# cyw20829 register map
Vendor: Cypress Semiconductor; Series: CYW20829; File version: 1.0
CPU: CM33 r0p1, little endian, MPU, FPU, VTOR, 3 interrupt priority bits
Registers are 32-bit, read-write, reset 0x0 unless marked. A register's access mark holds for its fields unless they carry their own. Offsets are from the block's base; [hi:lo] are bit positions; lines under a group give offsets from that group; {n}, {i} and the like mark numbered series; 'fields as' and 'values as' point back to an identical list; <NAME> marks a mode.

## SRSS (part 3 of 3) — SRSS Core Registers
Base 0x40200000
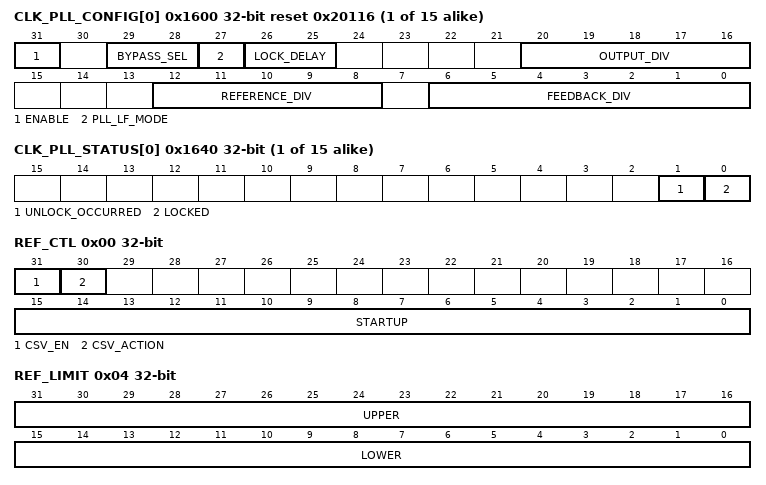
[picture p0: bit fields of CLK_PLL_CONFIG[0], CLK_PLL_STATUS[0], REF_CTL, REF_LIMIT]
{0x1600+4i} CLK_PLL_CONFIG[{i}] (i=0..14) reset 0x20116 — PLL Configuration Register
  [31] ENABLE — Master enable for PLL. Setup FEEDBACK_DIV, REFERENCE_DIV, and OUTPUT_DIV at least one cycle before setting ENABLE=1. Fpll = (FEEDBACK_DIV) * (Fref / REFERENCE_DIV) / (OUTPUT_DIV) 0: Block is disabled. When the PLL disables, hardware controls the bypass mux as described in BYPASS_SEL, before disabling the PLL circuit. 1: Block is enabled
  [29:28] BYPASS_SEL — Bypass mux located just after PLL output. This selection is glitch-free and can be changed while the PLL is running. When changing BYPASS_SEL, do not turn off the reference clock or PLL clock for five cycles (whichever is slower).
    0=AUTO (Automatic using lock indicator. When unlocked, automatically selects PLL reference input (bypass mode). When locked, automatically selects PLL output. If ENABLE=0, automatically selects PLL reference input.); 1=LOCKED_OR_NOTHING (Similar to AUTO, except the clock is gated off when unlocked. This is compatible with clock supervision, because the supervisors allow no clock during startup (until a timeout occurs), and the clock targets the proper frequency whenever it is running. If ENABLE=0, no clock is output.); 2=PLL_REF (Select PLL reference input (bypass mode). Ignores lock indicator); 3=PLL_OUT (Select PLL output. Ignores lock indicator. If ENABLE=0, no clock is output.)
  [27] PLL_LF_MODE — VCO frequency range selection. Configure this bit according to the targeted VCO frequency. Do not change this setting while the PLL is enabled. 0: VCO frequency is [200MHz, 400MHz] 1: VCO frequency is [170MHz, 200MHz)
  [26:25] LOCK_DELAY
  [20:16] OUTPUT_DIV — Control bits for Output divider. Set the divide value before enabling the PLL, and do not change it while PLL is enabled. 0: illegal (undefined behavior) 1: illegal (undefined behavior) 2: divide by 2. Suitable for direct usage as HFCLK source. ... 16: divide by 16. Suitable for direct usage as HFCLK source. >16: illegal (undefined behavior)
  [12:8] REFERENCE_DIV — Control bits for reference divider. Set the divide value before enabling the PLL, and do not change it while PLL is enabled. 0: illegal (undefined behavior) 1: divide by 1 ... 20: divide by 20 others: illegal (undefined behavior)
  [6:0] FEEDBACK_DIV — Control bits for feedback divider. Set the divide value before enabling the PLL, and do not change it while PLL is enabled. 0-21: illegal (undefined behavior) 22: divide by 22 ... 112: divide by 112 >112: illegal (undefined behavior)
{0x1640+4i} CLK_PLL_STATUS[{i}] (i=0..14) — PLL Status Register
  [1] UNLOCK_OCCURRED — This bit sets whenever the PLL Lock bit goes low, and stays set until cleared by firmware.
  [0] LOCKED ro — PLL Lock Indicator
0x1700 CSV_REF_SEL — Select CSV Reference clock for Active domain
  [2:0] REF_MUX — Selects a source for clock clk_ref_hf. Note that not all products support all clock sources. Selecting a clock source that is not supported will result in undefined behavior. It takes four cycles of the originally selected clock to switch away from it. Do not disable the original clock during this time.
    0=IMO (IMO - Internal R/C Oscillator); 1=EXTCLK (EXTCLK - External Clock Pin); 2=ECO (ECO - External-Crystal Oscillator); 3=ALTHF (ALTHF - Alternate High-Frequency clock input (product-specific clock)); 4=IHO (IHO - Internal High-speed Oscillator)
0x1710 CSV_REF group — CSV registers for the CSV Reference clock
  0x00 CSV group — Active domain Clock Supervisor (CSV) registers for CSV Reference clock
    0x00 REF_CTL — Clock Supervision Reference Control
      [31] CSV_EN — Enables clock supervision, both frequency and loss. CSV in Active domain: Clock supervision is reset during DeepSleep and Hibernate modes. When enabled it begins operating automatically after a DeepSleep wakeup, but it must be reconfigured after Hibernate wakeup. CSV in DeepSleep domain: Clock supervision is reset during Hibernate mode. It must be reconfigured after Hibernate wakeup. A CSV error detection is reported to the Fault structure, or instead it can generate a power reset.
      [30] CSV_ACTION — Specifies the action taken when an anomaly is detected on the monitored clock. CSV in DeepSleep domain always do a Fault report (which also wakes up the system).
        0=FAULT (Generate a fault); 1=RESET (Cause a power reset. This should only be used for clk_hf0.)
      [15:0] STARTUP — Startup delay time -1 (in reference clock cycles), after enable or DeepSleep wakeup, from reference clock start to monitored clock start. At a minimum (both clocks running): STARTUP >= (PERIOD +3) * FREQ_RATIO - UPPER, with FREQ_RATIO = (Reference frequency / Monitored frequency) On top of that the actual clock startup delay and the margin for accuracy of both clocks must be added.
    0x04 REF_LIMIT — Clock Supervision Reference Limits
      [31:16] UPPER — Cycle time upper limit. Set the upper limit -1, in reference clock cycles, before (or same time) the next monitored clock event must happen. If a monitored clock event does not happen before this limit is reached, or does not happen at all (clock loss), a CSV error is detected.
      [15:0] LOWER — Cycle time lower limit. Set the lower limit -1, in reference clock cycles, before the next monitored clock event is allowed to happen. If a monitored clock event happens before this limit is reached a CSV error is detected. LOWER must be at least 1 less than UPPER. In case the clocks are asynchronous LOWER must be at least 3 less than UPPER.
    0x08 MON_CTL — Clock Supervision Monitor Control
      [15:0] PERIOD — Period time. Set the Period -1, in monitored clock cycles, before the next monitored clock event happens. PERIOD <= (UPPER+1) / FREQ_RATIO -1, with FREQ_RATIO = (Reference frequency / Monitored frequency) In case the clocks are asynchronous: PERIOD <= UPPER / FREQ_RATIO -1 Additionally margin must be added for accuracy of both clocks.
0x1720 CSV_LF group — CSV registers for LF clock
  0x00 CSV group — LF clock Clock Supervisor registers
    0x00 REF_CTL — Clock Supervision Reference Control
      [31] CSV_EN — Enables clock supervision, both frequency and loss. CSV in Active domain: Clock supervision is reset during DeepSleep and Hibernate modes. When enabled it begins operating automatically after a DeepSleep wakeup, but it must be reconfigured after Hibernate wakeup. CSV in DeepSleep domain: Clock supervision is reset during Hibernate mode. It must be reconfigured after Hibernate wakeup. CSV in Backup domain: Clock supervision operates during Hibernate mode, can be configured to wake from Hibernate, and continues operating during reboot. A CSV error detection is reported to the Fault structure.
      [7:0] STARTUP — Startup delay time -1 (in reference clock cycles), after enable, from reference clock start to monitored clock start. At a minimum (both clocks running): STARTUP >= (PERIOD +3) * FREQ_RATIO - UPPER, with FREQ_RATIO = (Reference frequency / Monitored frequency) On top of that the actual clock startup delay and the margin for accuracy of both clocks must be added.
    0x04 REF_LIMIT — Clock Supervision Reference Limits
      [23:16] UPPER — Cycle time upper limit. Set the upper limit -1, in reference clock cycles, before (or same time) the next monitored clock event must happen. If a monitored clock event does not happen before this limit is reached, or does not happen at all (clock loss), a CSV error is detected.
      [7:0] LOWER — Cycle time lower limit. Set the lower limit -1, in reference clock cycles, before the next monitored clock event is allowed to happen. If a monitored clock event happens before this limit is reached a CSV error is detected. LOWER must be at least 1 less than UPPER. In case the clocks are asynchronous LOWER must be at least 3 less than UPPER.
    0x08 MON_CTL — Clock Supervision Monitor Control
      [7:0] PERIOD — Period time. Set the Period -1, in monitored clock cycles, before the next monitored clock event happens. PERIOD <= (UPPER+1) / FREQ_RATIO -1, with FREQ_RATIO = (Reference frequency / Monitored frequency) In case the clocks are asynchronous: PERIOD <= UPPER / FREQ_RATIO -1 Additionally margin must be added for accuracy of both clocks.
0x1730 CSV_ILO group — CSV registers for ILO clock
  0x00 CSV group — HVILO clock DeepSleep domain Clock Supervisor registers
    0x00 REF_CTL — Clock Supervision Reference Control
      fields as CSV_LF.CSV.REF_CTL
    0x04 REF_LIMIT — Clock Supervision Reference Limits
      fields as CSV_LF.CSV.REF_LIMIT
    0x08 MON_CTL — Clock Supervision Monitor Control
      fields as CSV_LF.CSV.MON_CTL
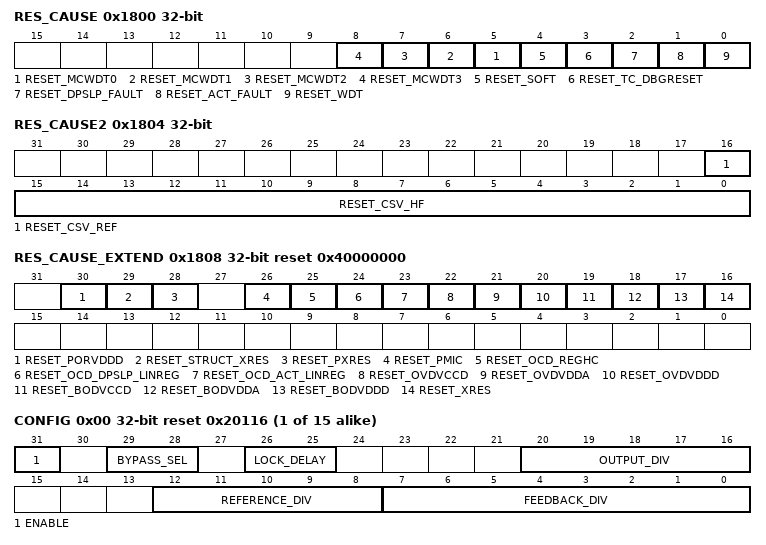
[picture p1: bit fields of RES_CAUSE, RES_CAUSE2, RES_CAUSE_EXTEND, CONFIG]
0x1800 RES_CAUSE — Reset Cause Observation Register
  [n+5] RESET_MCWDT{n} (n=0..3) — Multi-Counter Watchdog timer reset #{n}. This is a low-voltage cause bit that hardware clears when the low-voltage supply is initialized (see comments above).
  [4] RESET_SOFT — A CPU requested a system reset through it's SYSRESETREQ. This can be done via a debugger probe or in firmware. This is a low-voltage cause bit that hardware clears when the low-voltage supply is initialized (see comments above).
  [3] RESET_TC_DBGRESET — Test controller or debugger asserted reset. Only resets debug domain. This is a low-voltage cause bit that hardware clears when the low-voltage supply is initialized (see comments above).
  [2] RESET_DPSLP_FAULT
  [1] RESET_ACT_FAULT
  [0] RESET_WDT — A basic WatchDog Timer (WDT) reset has occurred since last power cycle. ULP products: This is a low-voltage cause bit that hardware clears when the low-voltage supply is initialized (see comments above). For products that support high-voltage cause detection, this bit blocks recording of other high-voltage cause bits, except RESET_PORVDDD. Hardware clears this bit during POR. This bit is not blocked by other HV cause bits.
0x1804 RES_CAUSE2 — Reset Cause Observation Register 2
  [16] RESET_CSV_REF — Clock supervision logic requested a reset due to loss or frequency violation of the reference clock source that is used to monitor the other HF clock sources.
  [15:0] RESET_CSV_HF — Clock supervision logic requested a reset due to loss or frequency violation of a high-frequency clock. Each bit index K corresponds to a HFCLK<K>. Unimplemented clock bits return zero.
0x1808 RES_CAUSE_EXTEND reset 0x40000000 — Extended Reset Cause Observation Register
  [30] RESET_PORVDDD — Indicator that a POR occurred. This is a high-voltage cause bit, and hardware clears the other bits when this one is set. It does not block further recording of other high-voltage causes.
  [29] RESET_STRUCT_XRES — Structural reset was asserted. This is a high-voltage cause bit that blocks recording of other high-voltage cause bits, except RESET_PORVDDD. Hardware clears this bit during POR. This bit is not blocked by other HV cause bits.
  [28] RESET_PXRES — PXRES triggered. This is a high-voltage cause bit that blocks recording of other high-voltage cause bits, except RESET_PORVDDD. Hardware clears this bit during POR. This bit is not blocked by other HV cause bits.
  [26] RESET_PMIC — PMIC status triggered a reset. If PMIC control is not present, hardware will never set this bit. This is a high-voltage cause bit that blocks recording of other high-voltage cause bits, except RESET_PORVDDD. Hardware clears this bit during POR.
  [25] RESET_OCD_REGHC — Overcurrent detection from REGHC (if present). If REGHC is not present, hardware will never set this bit. This is a high-voltage cause bit that blocks recording of other high-voltage cause bits, except RESET_PORVDDD. Hardware clears this bit during POR.
  [24] RESET_OCD_DPSLP_LINREG — Overcurrent detection on the internal VCCD supply when supplied by the DEEPSLEEP power mode linear regulator. This is a high-voltage cause bit that blocks recording of other high-voltage cause bits, except RESET_PORVDDD. Hardware clears this bit during POR.
  [23] RESET_OCD_ACT_LINREG — Overcurrent detection on the internal VCCD supply when supplied by the ACTIVE power mode linear regulator. This is a high-voltage cause bit that blocks recording of other high-voltage cause bits, except RESET_PORVDDD. Hardware clears this bit during POR.
  [22] RESET_OVDVCCD — Overvoltage detection on the internal core VCCD supply. This is a high-voltage cause bit that blocks recording of other high-voltage cause bits, except RESET_PORVDDD. Hardware clears this bit during POR.
  [21] RESET_OVDVDDA — Overvoltage detection on the external VDDA supply. This is a high-voltage cause bit that blocks recording of other high-voltage cause bits, except RESET_PORVDDD. Hardware clears this bit during POR.
  [20] RESET_OVDVDDD — Overvoltage detection on the external VDDD supply. This is a high-voltage cause bit that blocks recording of other high-voltage cause bits, except RESET_PORVDDD. Hardware clears this bit during POR.
  [19] RESET_BODVCCD — Internal VCCD core supply crossed the brown-out limit. Note that this detector will detect gross issues with the internal core supply, but may not catch all brown-out conditions. Functional and timing supervision (CSV, WDT) is provided to create fully failsafe internal crash detection. This is a high-voltage cause bit that blocks recording of other high-voltage cause bits, except RESET_PORVDDD. Hardware clears this bit during POR.
  [18] RESET_BODVDDA — External VDDA supply crossed the brown-out limit. This is a high-voltage cause bit that blocks recording of other high-voltage cause bits, except RESET_PORVDDD. Hardware clears this bit during POR.
  [17] RESET_BODVDDD — External VDDD supply crossed brown-out limit. Note that this cause will only be observable as long as the VDDD supply does not go below the POR (power on reset) detection limit. Below this limit it is not possible to reliably retain information in the device. This is a high-voltage cause bit that blocks recording of other high-voltage cause bits, except RESET_PORVDDD. Hardware clears this bit during POR.
  [16] RESET_XRES — External XRES pin was asserted. This is a high-voltage cause bit that blocks recording of other high-voltage cause bits, except RESET_PORVDDD. Hardware clears this bit during POR. This bit is not blocked by other HV cause bits.
0x1814 RES_PXRES_CTL wo — Programmable XRES Control Register
  [0] PXRES_TRIGGER — Triggers PXRES. This causes a full-scope reset and reboot.
{0x1900+0x10*i} CLK_PLL400M[{i}] (i=0..14) group — 400MHz PLL Configuration Register
  0x00 CONFIG reset 0x20116 — 400MHz PLL Configuration Register
    [31] ENABLE — Master enable for PLL. Setup FEEDBACK_DIV, REFERENCE_DIV, and OUTPUT_DIV at least one cycle before setting ENABLE=1. fOUT = (FEEDBACK_DIV + FRAC_EN*FRAC_DIV/2^24) * (fREF / REFERENCE_DIV) / (OUTPUT_DIV) 0: Block is disabled. When the PLL disables, hardware controls the bypass mux as described in BYPASS_SEL, before disabling the PLL circuit. 1: Block is enabled
    [29:28] BYPASS_SEL — Bypass mux located just after PLL output. This selection is glitch-free and can be changed while the PLL is running. When changing BYPASS_SEL, do not turn off the reference clock or PLL clock for five cycles (whichever is slower).
      0=AUTO (Automatic using lock indicator. When unlocked, automatically selects PLL reference input (bypass mode). When locked, automatically selects PLL output. If ENABLE=0, automatically selects PLL reference input.); 1=LOCKED_OR_NOTHING (Similar to AUTO, except the clock is gated off when unlocked. This is compatible with clock supervision, because the supervisors allow no clock during startup (until a timeout occurs), and the clock targets the proper frequency whenever it is running. If ENABLE=0, no clock is output.); 2=PLL_BYPASS (Select PLL reference input (bypass mode). Ignores lock indicator); 3=PLL_OUT (Select PLL output. Ignores lock indicator. If ENABLE=0, no clock is output.)
    [26:25] LOCK_DELAY
    [20:16] OUTPUT_DIV — Control bits for Output divider. Set the divide value before enabling the PLL, and do not change it while PLL is enabled. 0: illegal (undefined behavior) 1: illegal (undefined behavior) 2: divide by 2. Suitable for direct usage as HFCLK source. ... 16: divide by 16. Suitable for direct usage as HFCLK source. >16: illegal (undefined behavior)
    [12:8] REFERENCE_DIV — Control bits for reference divider. Set the divide value before enabling the PLL, and do not change it while PLL is enabled. 0: illegal (undefined behavior) 1: divide by 1 ... 16: divide by 16 others: illegal (undefined behavior) When using fractional mode, the jitter specs are met over the restricted range of 1 to 4, inclusive.
    [7:0] FEEDBACK_DIV — Control bits for feedback divider. Set the divide value before enabling the PLL, and do not change it while PLL is enabled. 0-15: illegal (undefined behavior) 16: divide by 16 ... 200: divide by 200 >200: illegal (undefined behavior) When using fractional mode, the jitter specs are met over the restricted range of 27 to 47, inclusive.
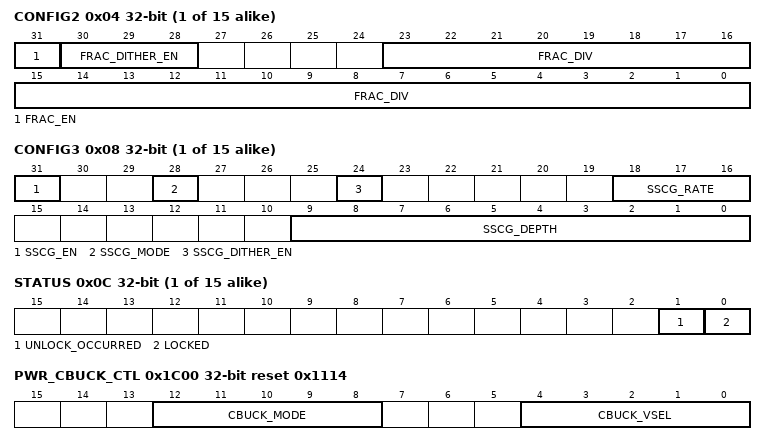
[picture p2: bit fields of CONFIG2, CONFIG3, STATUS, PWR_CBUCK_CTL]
  0x04 CONFIG2 — 400MHz PLL Configuration Register 2
    [31] FRAC_EN — Enables fractional division mode. When using fractional division mode, see CLK_PLL400M_CONFIG.LOCK_DELAY for an additional configuration requirement.
    [30:28] FRAC_DITHER_EN
    [23:0] FRAC_DIV — Control bits for fractional divider. This value is interpreted as a fraction of the PFD frequency, i.e. fPFD * (FRAC_DIV/2^24). This field can be dynamically updated within the 1000ppm control limit. It takes up to 115 AHB cycles to transfer the setting to the PLL, and writes that occur faster may be silently ignored and require the application to write again after the previous update has finished. Reading the register returns the accepted value. The PLL will start targeting the new value, but it may take significant time (milliseconds) to stabilize at the new average value. Do not change the FRAC_DIV setting while the PLL is initially locking.
  0x08 CONFIG3 — 400MHz PLL Configuration Register 3
    [31] SSCG_EN — Enables spreading mode. When using spreading, see CLK_PLL400M_CONFIG.LOCK_DELAY for an additional configuration requirement.
    [28] SSCG_MODE
    [24] SSCG_DITHER_EN — Enables dithering during spreading. 0: disabled 1: enabled
    [18:16] SSCG_RATE
    [9:0] SSCG_DEPTH
  0x0C STATUS — 400MHz PLL Status Register
    fields as CLK_PLL_STATUS[0]
0x1C00 PWR_CBUCK_CTL reset 0x1114 — Core Buck Control Register
  [12:8] CBUCK_MODE — CBUCK mode. Low ripple (high power) modes are intended for analog that needs low ripple. Low power mode is suitable for digital processing. The CBUCK mode is defined as = {mode*_sr_mode, mode*_sr_hp_submode[1:0], mode*_sr_lp_submode[1:0]} The actual CBUCK mode is the maximum of this setting and the settings of all enabled step-down regulators. 0x11: HP, PFM Auto, High-Low (default Active) 0x01: LP, PFM Auto, High-Low (DeepSleep) See s40power BROS for other settings
  [4:0] CBUCK_VSEL — Voltage output selection. This register is only reset by XRES, HIBERNATE wakeup, or supply supervision reset. The actual CBUCK voltage is the maximum of this setting, the settings for all enabled step-down regulators (see PWR_SDR*_CTL), and the minimum DEEPSLEEP setting (which is not user configurable). These settings follow the formula (0.76+0.02*CBUCK_VSEL). 0: 0.76V, 1: 0.78V, 2: 0.80V, 3: 0.82V, 4: 0.84V, 5: 0.86V, 6: 0.88V, 7: 0.90V, 8: 0.92V, 9: 0.94V, 10: 0.96V, 11: 0.98V, 12: 1.00V, 13: 1.02V, 14: 1.04V, 15: 1.06V, 16: 1.08V, 17: 1.10V, 18: 1.12V, 19: 1.14V, 20: 1.16V, 21: 1.18V, 22: 1.20V, 23: 1.22V, 24: 1.24V, 25: 1.26V, 26: 1.28V, 27: 1.30V, 28: 1.32V, 29: 1.34V, 30: 1.36V, 31: 1.38V.
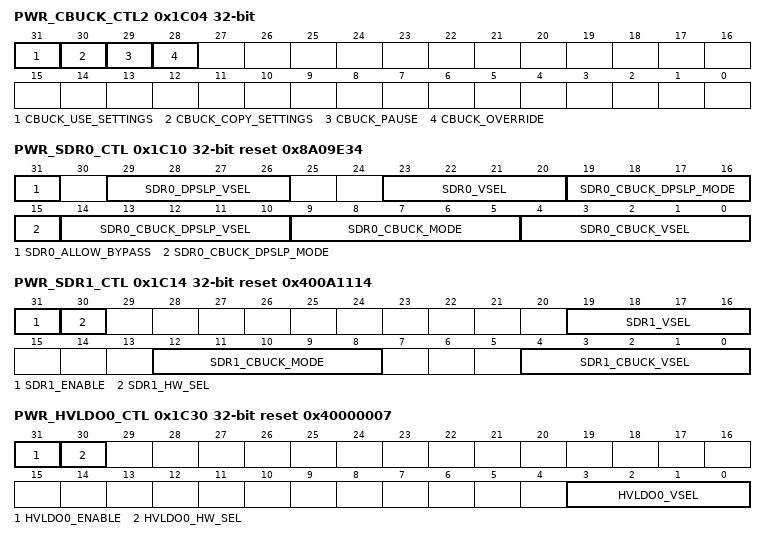
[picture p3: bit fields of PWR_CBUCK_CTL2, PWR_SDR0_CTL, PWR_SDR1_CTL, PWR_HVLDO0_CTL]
0x1C04 PWR_CBUCK_CTL2 — Core Buck Control Register 2
  [31] CBUCK_USE_SETTINGS — Causes the settings in PWR_CBUCK_CTL register to be included in the CBUCK setting decision. Can be used to override the normal hardware voltage behavior. Regardless of this bit, the extra settings in PWR_CBUCK_CTL register are not used during DEEPSLEEP.
  [30] CBUCK_COPY_SETTINGS — Copies the current CBUCK composite state to the fields in PWR_CBUCK_CTL register (CBUCK_VSEL and CBUCK_MODE). It is recommended to pause transitions using CBUCK_PAUSE to ensure the state does not change near the copy. After it is copied, the CBUCK_OVERRIDE bit can be used to hold the CBUCK in the current state. Note, reading this bit always returns 0. 0: no change 1: copy settings.
  [29] CBUCK_PAUSE — Pauses new dynamic CBUCK transitions. An already started transition will complete, but new dynamic transitions are paused. This can be used as part of a firmware sequence to change the voltage setting of an enabled stepdown regulator.
  [28] CBUCK_OVERRIDE — Forces the CBUCK to use the settings in PWR_CBUCK_CTL register, ignoring the other hardware requests. This can be used as part of a firmware algorithm to change the voltage of an enabled stepdown regulator. This bit is cleared by any reset.
0x1C08 PWR_CBUCK_CTL3 — Core Buck Control Register 3
  [31] CBUCK_INRUSH_SEL — CBUCK inrush limit selection. 0: 10mA limit. 1: 100mA limit.
0x1C0C PWR_CBUCK_STATUS ro — Core Buck Status Register
  [31] PMU_DONE — Indicates the power management unit is finished with a transition. 0: PMU busy 1: PMU done
0x1C10 PWR_SDR0_CTL reset 0x8A09E34 — Step Down Regulator 0 Control Register
  [31] SDR0_ALLOW_BYPASS — SDR0 bypass control. 0: Force SDR0 to regulate. 1: Allow SDR0 to bypass if the actual CBUCK voltage matches SDR0_CBUCK_VSEL.
  [29:26] SDR0_DPSLP_VSEL — SDR0 output voltage during DeepSleep. (See SDR0_VSEL for voltage table).
  [23:20] SDR0_VSEL — SDR0 output voltage. 0: 0.850V, 1: 0.875V, 2: 0.900V, 3: 0.925V, 4: 0.950V, 5: 0.975V, 6: 1.000V, 7: 1.025V, 8: 1.050V, 9: 1.075V, 10: 1.100V, 11: 1.125V, 12: 1.150V, 13: 1.175V, 14: 1.200V, 15: 1.225V
  [19:15] SDR0_CBUCK_DPSLP_MODE — DeepSleep CBUCK mode when using SDR0 (see PWR_CBUCK_CTL for mode table). Default DeepSleep
  [14:10] SDR0_CBUCK_DPSLP_VSEL — DeepSleep voltage selection of CBUCK (see PWR_CBUCK_CTL for voltage table). The voltage must be 60mV higher than the SDR output or the regulator output may bypass.
  [9:5] SDR0_CBUCK_MODE — Minimum CBUCK mode when using SDR0 (see PWR_CBUCK_CTL for mode table). Default Active
  [4:0] SDR0_CBUCK_VSEL — Minimum voltage selection of CBUCK when using this SDR0 (see PWR_CBUCK_CTL for voltage table). The voltage must be 60mV higher than the SDR output or the regulator output may bypass.
0x1C14 PWR_SDR1_CTL reset 0x400A1114 — Step Down Regulator 1 Control Register
  [31] SDR1_ENABLE — Enable for SDR1.
  [30] SDR1_HW_SEL — Selects hardware control for SDR1. 0: SDR1_ENABLE controls SDR1. Hardware controls are ignored. 1: SDR1_ENABLE is ignored and a hardware signal is used instead. Selecting this on products that don't have supporting hardware will disable SDR1.
  [19:16] SDR1_VSEL — SDR1 output voltage. 0: 0.850V, 1: 0.875V, 2: 0.900V, 3: 0.925V, 4: 0.950V, 5: 0.975V, 6: 1.000V, 7: 1.025V, 8: 1.050V, 9: 1.075V, 10: 1.100V, 11: 1.125V, 12: 1.150V, 13: 1.175V, 14: 1.200V, 15: 1.225V
  [12:8] SDR1_CBUCK_MODE — Minimum CBUCK mode when using SDR1 (see PWR_CBUCK_CTL for mode table).
  [4:0] SDR1_CBUCK_VSEL — Minimum voltage selection of CBUCK when using this SDR1 (see PWR_CBUCK_CTL for voltage table). The voltage must be 60mV higher than the SDR output or the regulator output may bypass.
0x1C30 PWR_HVLDO0_CTL reset 0x40000007 — HVLDO0 Control Register
  [31] HVLDO0_ENABLE
  [30] HVLDO0_HW_SEL — Selects hardware control for HVLDO0. 0: HVLDO0_ENABLE controls SDR1. Hardware controls are ignored. 1: HVLDO0_ENABLE is ignored and a hardware signal is used instead. Selecting this on products that don't have supporting hardware will disable HVLDO0.
  [3:0] HVLDO0_VSEL — HVLDO0 output voltage. 0: 1.8V, 1: 1.9V, 2: 2.0V, 3: 2.1V, 4: 2.2V, 5: 2.3V, 6: 2.4V, 7: 2.5V, 8: 2.6V, 9: 2.7V, 10: 2.8V, 11: 2.9V, 12: 3.0V, 13: 3.1V, 14: 3.2V, 15: 3.3V
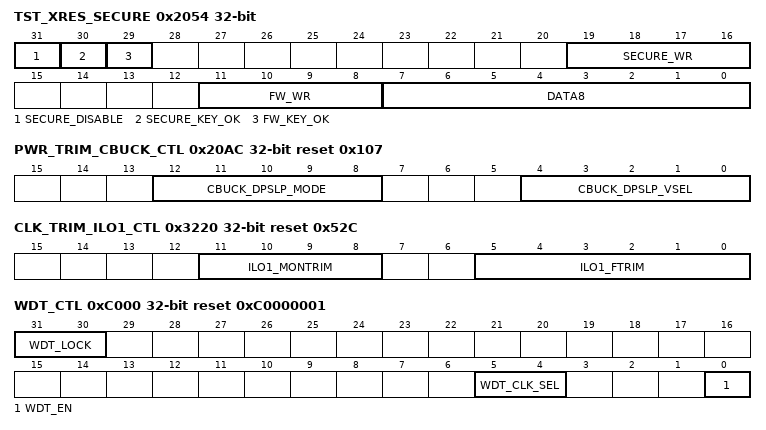
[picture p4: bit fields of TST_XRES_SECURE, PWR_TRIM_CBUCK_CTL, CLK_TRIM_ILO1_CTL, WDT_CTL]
0x2054 TST_XRES_SECURE — SECURE TEST and FIRMWARE TEST Key control register
  [31] SECURE_DISABLE — Disables the SECURE TEST key entry capability until next reset. Must not be set in the same write when any of the above *_WR bits are set or toggling.
  [30] SECURE_KEY_OK ro — Indicates that the 32-bit SECURE TEST key is observing the correct key. Secure key is not reset, but it will establish low after a deep power cycle that causes it to lose its written state.
  [29] FW_KEY_OK ro — Indicates that the 32-bit FIRMWARE TEST key is observing the correct key. Firmware key is reset by (A)XRES and STRUCT_XRES.
  [19:16] SECURE_WR — Latch enables for each of the 4 bytes in the 32-bit SECURE TEST key. Must be toggled high and then low while keeping DATA8 to the correct value.
  [11:8] FW_WR — Latch enables for each of the 4 bytes in the 32-bit FIRMWARE TEST key. Must be toggled high and then low while keeping DATA8 to the correct value.
  [7:0] DATA8 — Data byte to be set into either SECURE TEST or FIRMWARE TEST key. Must not be changed in the same write that is toggling any of the *_WR bits below,
0x20AC PWR_TRIM_CBUCK_CTL reset 0x107 — CBUCK Trim Register
  [12:8] CBUCK_DPSLP_MODE — The CBUCK mode setting to use during DEEPSLEEP.
  [4:0] CBUCK_DPSLP_VSEL — The CBUCK voltage setting to use during DEEPSLEEP.
0x301C CLK_TRIM_ECO_CTL reset 0x1F0000 — ECO Trim Register
  [21:16] ITRIM — Current Trim
0x3220 CLK_TRIM_ILO1_CTL reset 0x52C — ILO1 Trim Register
  [11:8] ILO1_MONTRIM — ILO1 internal monitor trim.
  [5:0] ILO1_FTRIM — ILO1 frequency trims. LSB step size is 1.5 percent (typical) of the frequency.
0xC000 WDT_CTL reset 0xC0000001 — Watchdog Counter Control Register (Type A)
  [31:30] WDT_LOCK — Prohibits writing to WDT_*, CLK_ILO_CONFIG, CLK_SELECT.LFCLK_SEL, and CLK_TRIM_ILO_CTL registers when not equal 0. Requires at least two different writes to unlock. A change in WDT_LOCK takes effect beginning with the next write cycle. Note that this field is 2 bits to force multiple writes only. It represents only a single write protect signal protecting all those registers at the same time. WDT will lock on any reset. This field is not retained during DEEPSLEEP or HIBERNATE mode, so the WDT will be locked after wakeup from these modes.
    0=NO_CHG (No effect); 1=CLR0 (Clears bit 0); 2=CLR1 (Clears bit 1); 3=SET01 (Sets both bits 0 and 1)
  [5:4] WDT_CLK_SEL — Select source for WDT. Not all products support all clock sources. Selecting a clock source that is not supported will result in undefined behavior. Writes to this field are ignored unless the WDT is unlock using WDT_LOCK register. It takes four cycles of the originally selected clock to switch away from it. Do not disable the original clock during this time.
    0=ILO (ILO - Internal Low-speed Oscillator); 1=PILO (PILO - Precision ILO. If present, if present); 2=BAK (BAK - Selected clk_bak source, if present. See BACKUP_CTL. This choice is not recommended for applications that rely upon the watchdog timer for safety or security, unless the product supports clock supervision of clk_bak (CSV_BAK). Generation of clk_bak is not protected by WDT_LOCK and is in a different memory region with potentially different security attributes.)
  [0] WDT_EN — Enable this watchdog timer. This field is retained during DEEPSLEEP and HIBERNATE modes.
0xC004 WDT_CNT — Watchdog Counter Count Register (Type A)
  [31:0] COUNTER — Current value of WDT Counter. The write feature of this register is for engineering use (DfV), have no synchronization, and can only be applied when the WDT is fully off. When writing, the value is updated immediately in the WDT counter, but it will read back as the old value until this register resynchronizes just after the negedge of ILO. Writes will be ignored if they occur when the WDT is enabled.
0xC008 WDT_MATCH reset 0x1000 — Watchdog Counter Match Register (Type A)
  [31:0] MATCH — Match value for Watchdog counter. Every time WDT_COUNTER reaches MATCH an interrupt is generated. Two unserviced interrupts will lead to a system reset (i.e. at the third match).
0xC00C WDT_MATCH2 reset 0x1F — Watchdog Counter Match Register 2 (Type A)
  [4:0] IGNORE_BITS_ABOVE — The bit index to be considered the MSB for matching. Bit indices above this setting are NOT checked against MATCH. This value provides control over the time-to-reset of the watchdog (which happens after 3 successive matches). The four LSBs cannot be ignored for matching. Settings <3 behave like a setting of 3. If the setting is higher than the number of bits in the WDT counter, all actual bits in the counter are matched.
0xD000 MCWDT_STRUCT group — Multi-Counter Watchdog Timer (Type A)
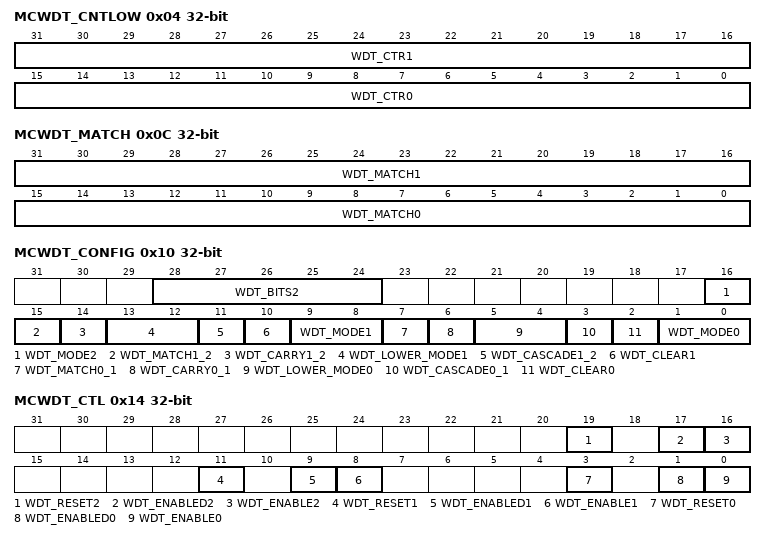
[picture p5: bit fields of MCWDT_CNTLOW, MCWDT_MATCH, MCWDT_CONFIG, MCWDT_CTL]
  0x04 MCWDT_CNTLOW — Multi-Counter Watchdog Sub-counters 0/1
    [31:16] WDT_CTR1 — Current value of sub-counter 1 for this MCWDT. Software writes are ignored when the sub-counter is enabled
    [15:0] WDT_CTR0 — Current value of sub-counter 0 for this MCWDT. Software writes are ignored when the sub-counter is enabled.
  0x08 MCWDT_CNTHIGH — Multi-Counter Watchdog Sub-counter 2
    [31:0] WDT_CTR2 — Current value of sub-counter 2 for this MCWDT. Software writes are ignored when the sub-counter is enabled
  0x0C MCWDT_MATCH — Multi-Counter Watchdog Counter Match Register
    [31:16] WDT_MATCH1 — Match value for sub-counter 1 of this MCWDT
    [15:0] WDT_MATCH0 — Match value for sub-counter 0 of this MCWDT
  0x10 MCWDT_CONFIG — Multi-Counter Watchdog Counter Configuration
    [28:24] WDT_BITS2 — Bit to observe for WDT_INT2: 0: Assert after bit0 of WDT_CTR2 toggles (one int every tick) ... 31: Assert after bit31 of WDT_CTR2 toggles (one int every 2^31 ticks)
    [16] WDT_MODE2 — Watchdog Counter 2 Mode.
      0=NOTHING (Free running counter with no interrupt requests); 1=INT (Free running counter with interrupt request that occurs one LFCLK cycle after the specified bit in CTR2 toggles (see WDT_BITS2).)
    [15] WDT_MATCH1_2 — Specifies matching behavior when WDT_CASCADE1_2==1. When WDT_CASCADE1_2==0, this bit is not used and match is based on counter 2 alone. 0: Match based on counter 2 alone. 1: Match based on counter 2 and counter 1 matching simultaneously.
    [14] WDT_CARRY1_2 — Carry out behavior that applies when WDT_CASCADE1_2==1. This bit is not used when WDT_CASCADE1_2==0. 0: carry out on counter 1 match. 1: carry out on counter 1 roll-over.
    [13:12] WDT_LOWER_MODE1 — Watchdog Counter Action on service before lower limit.
      0=NOTHING (Do nothing); 1=INT (Assert WDT_INTx); 2=RESET (Assert WDT Reset)
    [11] WDT_CASCADE1_2 — Cascade Watchdog Counters 1,2. Counter 2 increments the cycle after WDT_CTR1=WDT_MATCH1. It is allowed to cascade all three WDT counters. 0: Independent counters 1: Cascaded counters. When cascading all three counters, WDT_CLEAR1 must be 1.
    [10] WDT_CLEAR1 — Clear Watchdog Counter when WDT_CTR1==WDT_MATCH1. In other words WDT_CTR1 divides LFCLK by (WDT_MATCH1+1). 0: Free running counter 1: Clear on match. In this mode, the minimum legal setting of WDT_MATCH1 is 1.
    [9:8] WDT_MODE1 — Watchdog Counter Action on Match. Action is taken on the next increment after the values match (WDT_CTR1=WDT_MATCH1).
      0=NOTHING (Do nothing); 1=INT (Assert WDT_INTx); 2=RESET (Assert WDT Reset); 3=INT_THEN_RESET (Assert WDT_INTx, assert WDT Reset after 3rd unhandled interrupt)
    [7] WDT_MATCH0_1 — Specifies matching behavior when WDT_CASCADE0_1==1. When WDT_CASCADE0_1==0, this bit is not used and match is based on counter 1 alone. 0: Match based on counter 1 alone. 1: Match based on counter 1 and counter 0 matching simultaneously.
    [6] WDT_CARRY0_1 — Carry out behavior that applies when WDT_CASCADE0_1==1. This bit is not used when WDT_CASCADE0_1==0. 0: carry out on counter 0 match. 1: carry out on counter 0 roll-over.
    [5:4] WDT_LOWER_MODE0 — Watchdog Counter Action on service before lower limit.
      values as WDT_LOWER_MODE1
    [3] WDT_CASCADE0_1 — Cascade Watchdog Counters 0,1. Counter 1 increments the cycle after WDT_CTR0=WDT_MATCH0. 0: Independent counters 1: Cascaded counters
    [2] WDT_CLEAR0 — Clear Watchdog Counter when WDT_CTR0=WDT_MATCH0. In other words WDT_CTR0 divides LFCLK by (WDT_MATCH0+1). 0: Free running counter 1: Clear on match. In this mode, the minimum legal setting of WDT_MATCH0 is 1.
    [1:0] WDT_MODE0 — Watchdog Counter Action on Match. Action is taken on the next increment after the values match (WDT_CTR0=WDT_MATCH0).
      values as WDT_MODE1
  0x14 MCWDT_CTL — Multi-Counter Watchdog Counter Control
    [19] WDT_RESET2 — Resets counter 2 back to 0000. Hardware will reset this bit after counter was reset. This will take up to one LFCLK cycle to take effect.
    [17] WDT_ENABLED2 ro — Indicates actual state of counter. May lag WDT_ENABLE2 by up to two LFCLK cycles.
    [16] WDT_ENABLE2 — Enable subcounter 2. May take up to 2 LFCLK cycles to take effect. 0: Counter is disabled (not clocked) 1: Counter is enabled (counting up)
    [11] WDT_RESET1 — Resets counter 1 back to 0000. Hardware will reset this bit after counter was reset. This will take up to one LFCLK cycle to take effect.
    [9] WDT_ENABLED1 ro — Indicates actual state of counter. May lag WDT_ENABLE1 by up to two LFCLK cycles.
    [8] WDT_ENABLE1 — Enable subcounter 1. May take up to 2 LFCLK cycles to take effect. 0: Counter is disabled (not clocked) 1: Counter is enabled (counting up)
    [3] WDT_RESET0 — Resets counter 0 back to 0000. Hardware will reset this bit after counter was reset. This will take up to one LFCLK cycle to take effect.
    [1] WDT_ENABLED0 ro — Indicates actual state of counter. May lag WDT_ENABLE0 by up to two LFCLK cycles.
    [0] WDT_ENABLE0 — Enable subcounter 0. May take up to 2 LFCLK cycles to take effect. 0: Counter is disabled (not clocked) 1: Counter is enabled (counting up)
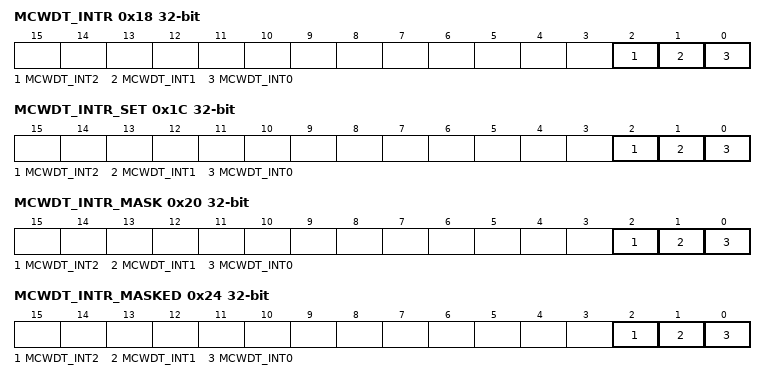
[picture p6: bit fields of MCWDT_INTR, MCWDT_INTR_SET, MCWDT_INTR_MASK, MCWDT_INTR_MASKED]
  0x18 MCWDT_INTR — Multi-Counter Watchdog Counter Interrupt Register
    [2] MCWDT_INT2 — MCWDT Interrupt Request for sub-counter 2. This bit is set by hardware as configured by this registers. This bit must be cleared by firmware. Clearing this bit also prevents Reset from happening when WDT_MODE2=3.
    [1] MCWDT_INT1 — MCWDT Interrupt Request for sub-counter 1. This bit is set by hardware as configured by this registers. This bit must be cleared by firmware. Clearing this bit also prevents Reset from happening when WDT_MODE1=3.
    [0] MCWDT_INT0 — MCWDT Interrupt Request for sub-counter 0. This bit is set by hardware as configured by this registers. This bit must be cleared by firmware. Clearing this bit also prevents Reset from happening when WDT_MODE0=3.
  0x1C MCWDT_INTR_SET — Multi-Counter Watchdog Counter Interrupt Set Register
    [2] MCWDT_INT2 — Set interrupt for MCWDT_INT2
    [1] MCWDT_INT1 — Set interrupt for MCWDT_INT1
    [0] MCWDT_INT0 — Set interrupt for MCWDT_INT0
  0x20 MCWDT_INTR_MASK — Multi-Counter Watchdog Counter Interrupt Mask Register
    [2] MCWDT_INT2 — Mask for sub-counter 2. This controls if the interrupt is forwarded to the CPU. 0: Interrupt is masked (not forwarded). 1: Interrupt is forwarded.
    [1] MCWDT_INT1 — Mask for sub-counter 1. This controls if the interrupt is forwarded to the CPU. 0: Interrupt is masked (not forwarded). 1: Interrupt is forwarded.
    [0] MCWDT_INT0 — Mask for sub-counter 0. This controls if the interrupt is forwarded to the CPU. 0: Interrupt is masked (not forwarded). 1: Interrupt is forwarded.
  0x24 MCWDT_INTR_MASKED ro — Multi-Counter Watchdog Counter Interrupt Masked Register
    [2] MCWDT_INT2 — Logical and of corresponding request and mask bits.
    [1] MCWDT_INT1 — Logical and of corresponding request and mask bits.
    [0] MCWDT_INT0 — Logical and of corresponding request and mask bits.
  0x28 MCWDT_LOCK — Multi-Counter Watchdog Counter Lock Register
    [31:30] MCWDT_LOCK — Prohibits writing control and configuration registers related to this MCWDT when not equal 0 (as specified in the other register descriptions). Requires at least two different writes to unlock. Note that this field is 2 bits to force multiple writes only. Each MCWDT has a separate local lock. LFCLK settings are locked by the global WDT_LOCK register, and this register has no effect on that.
      values as WDT_CTL.WDT_LOCK
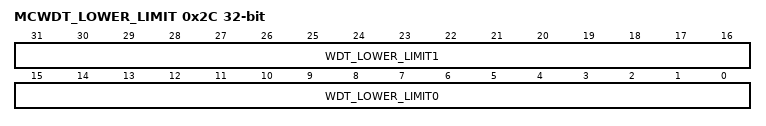
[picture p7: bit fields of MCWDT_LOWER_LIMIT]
  0x2C MCWDT_LOWER_LIMIT — Multi-Counter Watchdog Counter Lower Limit Register
    [31:16] WDT_LOWER_LIMIT1 — Lower limit for sub-counter 1 of this MCWDT
    [15:0] WDT_LOWER_LIMIT0 — Lower limit for sub-counter 0 of this MCWDT

## Notices in the file
(c) (2016-2021), Cypress Semiconductor Corporation (an Infineon company)
or an affiliate of Cypress Semiconductor Corporation.
SPDX-License-Identifier: Apache-2.0
Licensed under the Apache License, Version 2.0 (the "License");
you may not use this file except in compliance with the License.
You may obtain a copy of the License at
http://www.apache.org/licenses/LICENSE-2.0
Unless required by applicable law or agreed to in writing, software
distributed under the License is distributed on an "AS IS" BASIS,
WITHOUT WARRANTIES OR CONDITIONS OF ANY KIND, either express or implied.
See the License for the specific language governing permissions and
limitations under the License.
